# LFMXO5_25 register map
Vendor: Latticsemi.com; Series: LFMXO5; File version: 1.0
Registers are 32-bit, read-write, reset 0x0 unless marked. A register's access mark holds for its fields unless they carry their own. Offsets are from the block's base; [hi:lo] are bit positions.

## i3c_s_inst
Base 0x00010800
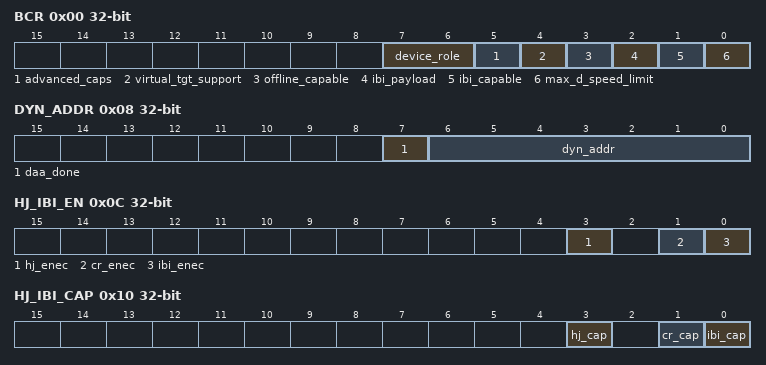
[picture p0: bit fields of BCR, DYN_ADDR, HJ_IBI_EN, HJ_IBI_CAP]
0x00 BCR ro — Target Bus Characteristics Register
  [7:6] device_role — 2'b00 - I3C Target, 2'b01 - I3C Controller-capable (Not implemented in this IP), Others - Reserved for future definition by MIPI Alliance I3C WG
  [5] advanced_caps — 0 - Does not support optional advanced capabilities., 1 - Supports optional advanced capabilities. When Target is configured with IBI capability and IBI payload, this is set to 1 for optional Pending Read MDB support.
  [4] virtual_tgt_support — 0 - Is not a Virtual Target and does not expose other downstream Device(s), 1 - Is a Virtual Target, or exposes other downstream Device(s)
  [3] offline_capable — 0 - Device will always respond to I3C Bus commands, 1 - Device will not always respond to I3C Bus Commands
  [2] ibi_payload — From IBI Payload Size attiribute. 0 - If IBI Payload Size attribute is set to 0. No data bytes follow the IBI., 1 - If IBI Payload Size attribute is set to greater than or equal to 1. One data byte (MDB) shall follow the accepted IBI, and additional data bytes may follow
  [1] ibi_capable — From IBI Capable attribute. 0 - Not capable., 1 - Capable.
  [0] max_d_speed_limit — From Maximum Data Speed Limitation attribute. 0 - No limitation., 1 - With limitation. Controller shall use GETMXDS CCC to get specific limitation from Target.
0x04 DCR ro — Target Device Characteristics Register
  [7:0] dcr — Device ID set by User through DCR attribute. 255 available codes for describing the type of sensor or Device (e.g., accelerometer, gyroscope, composite Devices). Default value is 8'b0 for generic Device.
0x08 DYN_ADDR ro — Assigned dynamic address and done flag
  [7] daa_done — 0 - DA is not yet assigned or is reset by RSTDAA CCC.,1 - DA is assigned via ENTDAA, SETNEWDA, SETAASA or SETDASA CCC
  [6:0] dyn_addr — Dynamic Address Assigned to I3C Target
0x0C HJ_IBI_EN ro — Hot-Join and IBI enable from Controller via ENEC/DISEC CCC
  [3] hj_enec — Hot-Join Enable by Controller. 0 - Target-initiated Hot-Join is not allowed on the I3C bus, 1 - Target-initiated Hot-Join is allowed on the I3C bus
  [1] cr_enec — Controller Role Request Enable by Controller. 0 - Target-initiated Controller Role Request is not allowed on the I3C bus, 1 - Target-initiated Controller Role Request is allowed on the I3C bus
  [0] ibi_enec — IBI Enable by Controller. 0 - Target-initiated interrupts are not allowed on the I3C bus, 1 - Target-initiated interrupts are allowed on the I3C bus
0x10 HJ_IBI_CAP ro — Hot-Join and IBI capability configured by User using attributes
  [3] hj_cap — 0 - Target device is configured without Hot-Join Capability, 1 - Target device is configured with Hot-Join Capability
  [1] cr_cap — 0 - Target device is configured without Secondary-Controller Capability, 1 - Target device is configured with Secondary-Controller Capability
  [0] ibi_cap — 0 - Target device is configured without IBI Capability, 1 - Target device is configured with IBI Capability
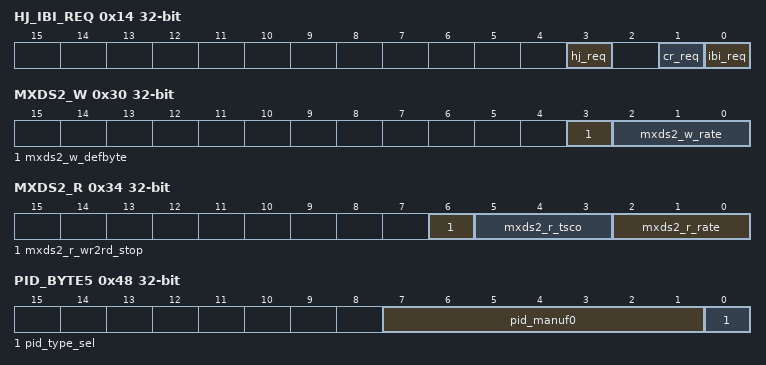
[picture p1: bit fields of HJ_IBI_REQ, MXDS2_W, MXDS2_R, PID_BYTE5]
0x14 HJ_IBI_REQ — Hot-Join and IBI request from User.
  [3] hj_req — When set to High, Target will initiate Hot-Join request at the next valid opportunity. Reset to 0 when Hot-Join is done or disabled by the Controller.
  [1] cr_req — When set to High, Target will initiate Controller Role Request at the next valid opportunity. Reset to 0 when Controller Role Request is done or disabled by the Controller.
  [0] ibi_req — When set to High, Target will initiate IBI at the next valid opportunity. Reset to 0 when IBI is done or disabled by the Controller.
0x18 HJ_IBI_RETRY — Number of retries for Hot-Join and IBI.
  [7:0] hj_ibi_retry — Indicates number of times the Target retries Hot-Join or IBI when it is NACKed by the Controller. When set to 0, number of tries is not limited.
0x1C MWL_MSB ro — Most significant byte of Maximum Write Length set by the Controller
  [7:0] mwl_msb — Most Significant Byte of maximum write length set by I3C Controller via SETMWL CCC. If SETMWL is greater than default value 512 (FIFO size), MWL will be set to 512.
0x20 MWL_LSB ro — Least significant byte of Maximum Write Length set by the Controller
  [7:0] mwl_lsb — Least Significant Byte of maximum write length set by I3C Controller via SETMWL CCC. If SETMWL is greater than default value 512 (FIFO size), MWL will be set to 512.
0x24 MRL_MSB ro — Most significant byte of Maximum Read Length set by the Controller
  [7:0] mrl_msb — Most Significant Byte of maximum read length set by I3C Controller via SETMRL CCC. If SETMRL is greater than default value 512 (FIFO size), MRL will be set to 512.
0x28 MRL_LSB ro — Least significant byte of Maximum Read Length set by the Controller
  [7:0] mrl_lsb — Least Significant Byte of maximum read length set by I3C Controller via SETMRL CCC. If SETMRL is greater than default value 512 (FIFO size), MRL will be set to 512.
0x2C MAX_IBI_PAYLD ro — Maximum IBI Payload Size set by the Controller. Applicable only when Target is configured with IBI capability and IBI payload is set to greater than or equal to 1.
  [7:0] max_ibi_payld — Maximum IBI Payload set by I3C Controller via SETMRL CCC. If value is greater than FIFO size, register will be set to FIFO size. Unlimited payload size is not supported in this IP.
0x30 MXDS2_W — Applicable only when Target is configured with Maximum Data Speed Limitation
  [3] mxds2_w_defbyte ro — 0 - Target does not support defining byte for GETMXDS CCC., 1 - Target supports defining byte for GETMXDS CCC.
  [2:0] mxds2_w_rate — Maximum Sustained Data Rate for non-CCC Messages sent by Controller Device to Target Device. 0 - fSCL Max (default value), 1 - 8 MHz, 2 - 6 MHz, 3 - 4 MHz, 4 - 2 MHz, Others - Reserved for future use by MIPI Alliance
0x34 MXDS2_R — Applicable only when Target is configured with Maximum Data Speed Limitation
  [6] mxds2_r_wr2rd_stop ro — If maximum read turnaround time is not 0, then this field is used to tell the Controller whether the Target permits the Write-to-Read to be split by a STOP. 0 - STOP would cancel the Read, 1 - The Target permits the Write-to-Read to be split by a STOP (not supported in this IP)
  [5:3] mxds2_r_tsco — Clock to Data Turnaround Time (tSCO). 0 - less than or equal to 8 ns (default value), 1 - less than or equal to 9 ns, 2 - less than or equal to 10 ns, 3 - less than or equal to 11 ns, 4 - less than or equal to 12 ns, 5, 6 - Reserved for future use by MIPI Alliance, 7 - tSCO is > 12 ns, and is reported by private agreement
  [2:0] mxds2_r_rate — Maximum Sustained Data Rate for non-CCC Messages sent by Target Device to Controller Device. 0 - fSCL Max (default value), 1 - 8 MHz, 2 - 6 MHz, 3 - 4 MHz, 4 - 2 MHz, Others - Reserved for future use by MIPI Alliance
0x38 MAX_RDTURN_B2 — Applicable only when Target is configured with Maximum Data Speed Limitation
  [7:0] max_rdturn_b2 — Maximum Read Turnaround Time in us. Most significant byte of 24-bit field that can encode turnaround times from 0.0 seconds to 16 seconds.
0x3C MAX_RDTURN_B1 — Applicable only when Target is configured with Maximum Data Speed Limitation
  [7:0] max_rdturn_b1 — Maximum Read Turnaround Time in us. Middle byte of 24-bit field that can encode turnaround times from 0.0 seconds to 16 seconds.
0x40 MAX_RDTURN_B0 — Applicable only when Target is configured with Maximum Data Speed Limitation
  [7:0] max_rdturn_b0 — Maximum Read Turnaround Time in us. Least significant byte of 24-bit field that can encode turnaround times from 0.0 seconds to 16 seconds.
0x44 PID_BYTE6 — 6th Byte of Target Device PID.
  [7:0] pid_manuf1 — Bits 14:7 of 15-bit MIPI Manufacturer ID. Reset value may be configured by User via Manufacturer ID attribute.
0x48 PID_BYTE5 — 5th Byte of Target Device PID.
  [7:1] pid_manuf0 — Bits 6:0 of 15-bit MIPI Manufacturer ID. Reset value may be configured by User via Manufacturer ID attribute.
  [0] pid_type_sel ro — Provisioned ID type selector. 0 - Vendor Fixed Value, 1 - Random value generated by device (Not supported in this IP)
0x4C PID_BYTE4 — 4th Byte of Target Device PID.
  [7:0] pid_part1 — Bits 15:8 of 16-bit Part ID when pid_type_sel is 0. The meaning of this 16-bit field is left to the Device vendor to define. Reset value may be configured by User via Part ID attribute.
0x50 PID_BYTE3 — 3rd Byte of Target Device PID.
  [7:0] pid_part0 — Bits 7:0 of 16-bit Part ID when pid_type_sel is 0. The meaning of this 16-bit field is left to the Device vendor to define. Reset value may be configured by User via Part ID attribute.
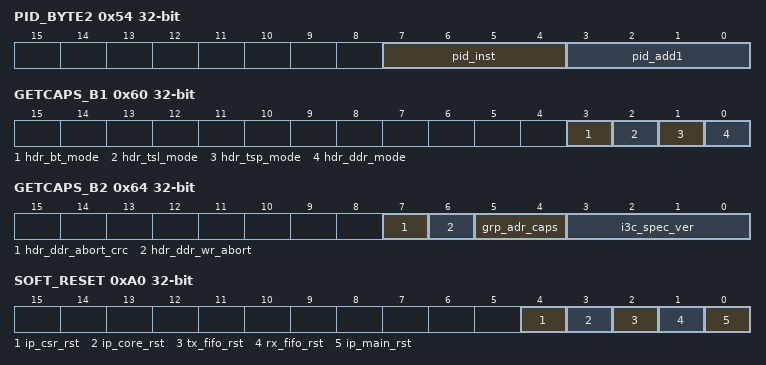
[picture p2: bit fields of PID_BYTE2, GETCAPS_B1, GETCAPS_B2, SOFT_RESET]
0x54 PID_BYTE2 — 2nd Byte of Target Device PID.
  [7:4] pid_inst — Instance ID field that should identify the individual Device, using a method selected by the system designer (e.g., straps, fuses, non-volatile memory, or another appropriate method). Reset value may be configured by User via Instance ID attribute.
  [3:0] pid_add1 — Bits 11:8 of 12-bit Additional ID for definitions with additional meaning (e.g., Deeper device characteristics that may optionally include Device Characteristics Register values). Reset value may be configured by User via Additional ID attribute.
0x58 PID_BYTE1 — 1st Byte of Target Device PID.
  [7:0] pid_add0 — Bits 7:0 of 12-bit Additional ID for definitions with additional meaning (e.g., Deeper device characteristics that may optionally include Device Characteristics Register values). Reset value may be configured by User via Additional ID attribute.
0x5C STAT_ADDR — 1st Byte of Target Device PID.
  [6:0] stat_addr — Target Static Address assigned by User. Reset value may be configured by User via Static Address attribute. If static address is disabled, reset value is 0.
0x60 GETCAPS_B1 ro — Device capabilities that Target returns when Controller sends GETCAPS CCC.
  [3] hdr_bt_mode — Fixed to 0. HDR-BT mode is not supported.
  [2] hdr_tsl_mode — Fixed to 0. HDR-BT mode is not supported.
  [1] hdr_tsp_mode — Fixed to 0. HDR-BT mode is not supported.
  [0] hdr_ddr_mode — Set to 1 when device is configured with HDR capability. Only HDR-DDR mode is supported.
0x64 GETCAPS_B2 ro — Device capabilities that Target returns when Controller sends GETCAPS CCC.
  [7] hdr_ddr_abort_crc — I3C Target capability of emitting the CRC Word when a transaction in HDR-DDR Mode is aborted. Set to 1 when device is configured with HDR capability. 0 - No, 1 - Yes
  [6] hdr_ddr_wr_abort — I3C Target capability of issuing the Write Abort in HDR-DDR Mode. Set to 1 when device is configured with HDR capability. 0 - No, 1 - Yes
  [5:4] grp_adr_caps — Indicates the Group Address function capabilities of this I3C Device. Fixed to 0. IP does not support Group Address function.
  [3:0] i3c_spec_ver — Indicates the minor version number of the MIPI I3C Specification with which this I3C v1.x Device complies (i.e., the 'x' in I3C v1.x). Setting to 0x is illegal.
0x68 GETCAPS_B3 ro — Device capabilities that Target returns when Controller sends GETCAPS CCC.
  [6] pend_rd_mdb — I3C Target support for IBI with Pending Read Notification MDB, which the Controller shall then follow with a Private Read request to fetch the data. Set to 1 when device is configured with IBI with MDB capability. 0 - No, 1 - Yes
  [6:5] hdr_bt_crc32 — I3C Target support CRC-32 data integrity verification in HDR Bulk Transport Mode. 0 - No, 1 - Yes (Not supported in this IP)
  [6:4] getstatus_defbyte — I3C Target support for defining byte in GETSTATUS CCC. 0 - No, 1 - Yes (Not supported in this IP)
  [6:3] getcaps_defbyte — I3C Target support for defining byte in GETCAPS CCC. 0 - No, 1 - Yes (Not supported in this IP)
  [6:2] d2dxfer_ibi — I3C Target capability to initiate Device to Device (D2D) Transfer using IBI with MDB 0x37. 0 - No, 1 - Yes (Not supported in this IP)
  [6:1] d2dxfer — I3C Target support for D2D transfers either as a Source or a Subscriber/Receiver. 0 - No, 1 - Yes (Not supported in this IP)
  [6:0] ml_data_xfer — I3C Target support for Multi-Lane data transfer. 0 - No, 1 - Yes (Not supported in this IP)
0x70 OSC_INACCURACY — Inaccuracy of Target's internal oscillator.
  [7:0] osc_inaccuracy — Describes the maximum variation of the Target's internal oscillator in 1/10th percent (0.1%) increments, up to 25.5%.
0x80 RX_FIFO ro — Receive FIFO
  [7:0] rx_fifo — Data bytes received from I3C bus are stored in this FIFO. User can get the received data by reading from this address multiple times depending on the number of data bytes to be read. User may read rxfifo_not_empty interrupt status register (Interrupt Status 2 Bit 6) first to determine if there is data to be read from rx_fifo.
0x88 TX_FIFO — Transmit FIFO
  [7:0] tx_fifo — Data to be sent to I3C bus are stored in this FIFO. User can do multiple writes to this address depending on the number of data bytes to be written. Reading from this address will indicate txfifo_empty status (0x1 - Empty, 0x - Not Empty).
0xA0 SOFT_RESET
  [4] ip_csr_rst — When set to high, resets the IP read-write and write-only registers only. Auto-clear.
  [3] ip_core_rst — When set to high, resets the internal state of I3C Target Core only (including Tx and Rx FIFO). Dynamic address and configurations via CCCs are not reset.
  [2] tx_fifo_rst — When set to high, resets the Tx FIFO only. Auto-clear.
  [1] rx_fifo_rst — When set to high, resets the Rx FIFO only. Auto-clear.
  [0] ip_main_rst — When set to high, resets the whole IP including registers, FIFO, dynamic address, and CCC configurations. Auto-clear.
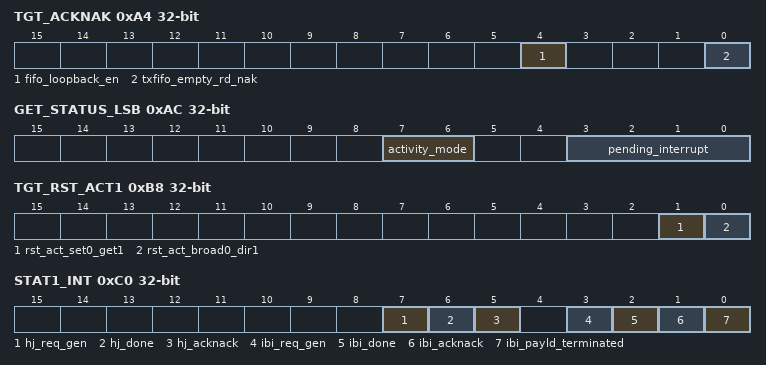
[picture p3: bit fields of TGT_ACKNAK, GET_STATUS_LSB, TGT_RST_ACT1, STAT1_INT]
0xA4 TGT_ACKNAK — Target Response
  [4] fifo_loopback_en — 0 - Data written through Private Write will be read from Rx FIFO. Data written to Tx FIFO will be read through Private Read. 1 - Data written through Private Write will be stored in Rx FIFO and transferred to Tx FIFO to be read through Private Read. Data written to the Tx FIFO by the User can still be read through Private Read.
  [0] txfifo_empty_rd_nak — Target response when Controller reads but Tx FIFO is empty 0 - In SDR mode, Target will ACK its Address and return 0xFF read data then End-of-Message by pulling SDA Low at T-bit. If I3C bus is in HDR mode and Target is configured with HDR capability, Target will ACK its address and return 0x data then end Read. 1 - Target will NACK its Address
0xA8 GET_STATUS_MSB — Most significant byte that the Target returns when Controller sends GETSTATUS CCC
  [7:0] get_status_msb — Reserved for vendor-specific meaning.
0xAC GET_STATUS_LSB — Least significant byte that the Target returns when Controller sends GETSTATUS CCC
  [7:6] activity_mode — Contains the 2-bit ID of the Target Device's current activity mode. For Target devices without secondary controller capability, the meanings of this value will depend upon a private contract between the Target and the Controller.
  [3:0] pending_interrupt — Contains the interrupt number of any pending interrupt, or 0 if no interrupts are pending.
0xB0 BUS_ACT_STATE ro — Least significant byte that the Target returns when Controller sends GETSTATUS CCC
  [1:0] bus_act — When bus_act_rcvd is set to 1, this register indicates the activity state received. Write 1 to clear. 0 - 1 us (Latency-free,operation), 1 - 100 us, 2 - 2ms, 3 - 50ms (Lowest-activity operation)
0xB4 TGT_RST_ACT0 ro — Target Reset Action Information 1
  [7:0] rst_act — Target Reset Action configured by the Controller via Defining Byte of RSTACT CCC. When Target Reset Pattern is received after RSTACT CCC, User shall perform the configured reset action.
0xB8 TGT_RST_ACT1 ro — Target Reset Action Information 2
  [1] rst_act_set0_get1 — 0 - Controller configured Target Reset Action by Direct SET RSTACT CCC, 1 - Controller configured Target Reset Action by Direct GET RSTACT CCC
  [0] rst_act_broad0_dir1 — 0 - Controller configured Target Reset Action by Broadcast RSTACT CCC, 1 - Controller configured Target Reset Action by Direct Set/Get RSTACT CCC
0xBC TGT_RST_ACT2 ro — Target Reset Action Information 3
  [7:0] rst_act_set — Target Reset Action configured by the Controller via Defining Byte of Direct SET RSTACT CCC. This is the value returned by Target when Controller sends Direct GET CCC.
0xC0 STAT1_INT — Interrupt Status 1
  [7] hj_req_gen — When set to 1, Hot-Join request is generated by Target. Write 1 to clear.
  [6] hj_done — When set to 1, Hot-Join address with Write bit is transmitted by Target and Controller has either ACKed or NACKed for HJ_IBI_RETRY times. Write 1 to clear.
  [5] hj_acknack — When set to 1, Hot-Join is NACKed by Controller after HJ_IBI_RETRY times. Write 1 to clear.
  [3] ibi_req_gen — When set to 1, IBI request is generated by Target. Write 1 to clear.
  [2] ibi_done — When set to 1, Target Address with Read bit has been transmitted by Target and Controller has either ACKED or NACKed the request for HJ_IBI_RETRY times. If with payload, IBI payload has been transmitted and finished either by End-of-Data (from Target) or STOP (from Controller). Write 1 to clear.
  [1] ibi_acknack — When set to 1, IBI is NACKed by Controller after HJ_IBI_RETRY times. Write 1 to clear.
  [0] ibi_payld_terminated — When set to 1, Controller aborted reading complete IBI payload. Write 1 to clear.
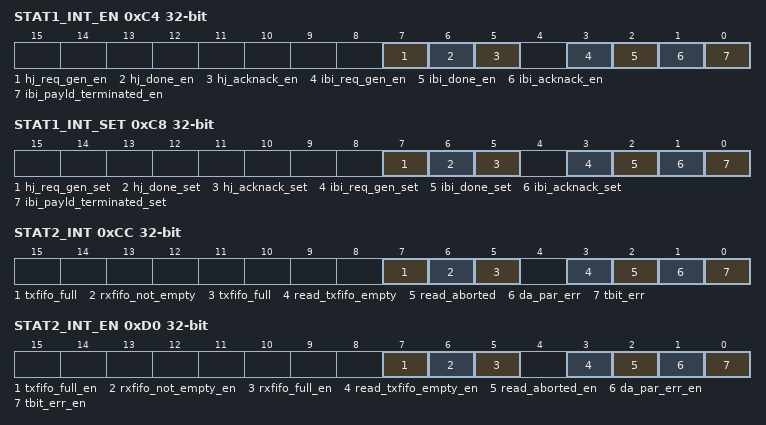
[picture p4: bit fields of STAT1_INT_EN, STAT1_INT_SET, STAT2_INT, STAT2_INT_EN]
0xC4 STAT1_INT_EN — Interrupt Status Enable 1
  [7] hj_req_gen_en — When set to 1, corresponding interrupt status 1 is enabled.
  [6] hj_done_en — When set to 1, corresponding interrupt status 1 is enabled.
  [5] hj_acknack_en — When set to 1, corresponding interrupt status 1 is enabled.
  [3] ibi_req_gen_en — When set to 1, corresponding interrupt status 1 is enabled.
  [2] ibi_done_en — When set to 1, corresponding interrupt status 1 is enabled.
  [1] ibi_acknack_en — When set to 1, corresponding interrupt status 1 is enabled.
  [0] ibi_payld_terminated_en — When set to 1, corresponding interrupt status 1 is enabled.
0xC8 STAT1_INT_SET wo — Interrupt Status Set 1
  [7] hj_req_gen_set — Manually set corresponding interrupt status 1 to 1.
  [6] hj_done_set — Manually set corresponding interrupt status 1 to 1.
  [5] hj_acknack_set — Manually set corresponding interrupt status 1 to 1.
  [3] ibi_req_gen_set — Manually set corresponding interrupt status 1 to 1.
  [2] ibi_done_set — Manually set corresponding interrupt status 1 to 1.
  [1] ibi_acknack_set — Manually set corresponding interrupt status 1 to 1.
  [0] ibi_payld_terminated_set — Manually set corresponding interrupt status 1 to 1.
0xCC STAT2_INT — Interrupt Status 2
  [7] txfifo_full — When set to 1, it indicates Tx FIFO is full. Write 1 to clear.
  [6] rxfifo_not_empty — When set to 1, it indicates that Rx FIFO is not empty. Write 1 to clear.
  [5] txfifo_full — When set to 1, it indicates Rx FIFO is full. Write 1 to clear.
  [3] read_txfifo_empty — When set to 1, Controller initiated Read but Tx FIFO is empty. Write 1 to clear.
  [2] read_aborted — When set to 1, Read is aborted early by Controller. Write 1 to clear.
  [1] da_par_err — When set to 1, parity bit error in dynamic address assignment occurred. Write 1 to clear.
  [0] tbit_err — When set to 1, data T-bit Error occurred. Write 1 to clear.
0xD0 STAT2_INT_EN — Interrupt Status Enable 2
  [7] txfifo_full_en — When set to 1, corresponding interrupt status 2 is enabled.
  [6] rxfifo_not_empty_en — When set to 1, corresponding interrupt status 2 is enabled.
  [5] rxfifo_full_en — When set to 1, corresponding interrupt status 2 is enabled.
  [3] read_txfifo_empty_en — When set to 1, corresponding interrupt status 2 is enabled.
  [2] read_aborted_en — When set to 1, corresponding interrupt status 2 is enabled.
  [1] da_par_err_en — When set to 1, corresponding interrupt status 2 is enabled.
  [0] tbit_err_en — When set to 1, corresponding interrupt status 2 is enabled.
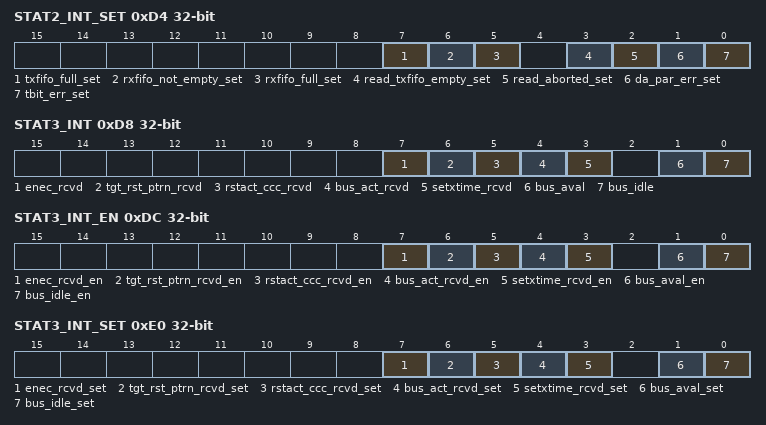
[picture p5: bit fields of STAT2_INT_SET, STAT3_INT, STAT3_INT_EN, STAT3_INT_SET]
0xD4 STAT2_INT_SET wo — Interrupt Status Set 2
  [7] txfifo_full_set — Manually set corresponding interrupt status 2 to 1.
  [6] rxfifo_not_empty_set — Manually set corresponding interrupt status 2 to 1.
  [5] rxfifo_full_set — Manually set corresponding interrupt status 2 to 1.
  [3] read_txfifo_empty_set — Manually set corresponding interrupt status 2 to 1.
  [2] read_aborted_set — Manually set corresponding interrupt status 2 to 1.
  [1] da_par_err_set — Manually set corresponding interrupt status 2 to 1.
  [0] tbit_err_set — Manually set corresponding interrupt status 2 to 1.
0xD8 STAT3_INT — Interrupt Status 3
  [7] enec_rcvd — When set to 1, Target received Broadcast/Direct ENEC/DISEC CCC from Controller. Write 1 to clear.
  [6] tgt_rst_ptrn_rcvd — When set to 1, Target received Target Reset Pattern from Controller. Write 1 to clear.
  [5] rstact_ccc_rcvd — When set to 1, Target received RSTACT CCC from Controller. Write 1 to clear.
  [4] bus_act_rcvd — When set to 1, Target received ENTASx CCC from Controller Write 1 to clear.
  [3] setxtime_rcvd — When set to 1, Target received SETXTIME with supported sub-command byte from Controller. Write 1 to clear.
  [1] bus_aval — When set to 1, I3C bus is in Bus Available condition. Write 1 to clear.
  [0] bus_idle — When set to 1, I3C bus is in Bus Idle condition. Write 1 to clear.
0xDC STAT3_INT_EN — Interrupt Status Enable 3
  [7] enec_rcvd_en — When set to 1, corresponding interrupt status 3 is enabled.
  [6] tgt_rst_ptrn_rcvd_en — When set to 1, corresponding interrupt status 3 is enabled.
  [5] rstact_ccc_rcvd_en — When set to 1, corresponding interrupt status 3 is enabled.
  [4] bus_act_rcvd_en — When set to 1, corresponding interrupt status 3 is enabled.
  [3] setxtime_rcvd_en — When set to 1, corresponding interrupt status 3 is enabled.
  [1] bus_aval_en — When set to 1, corresponding interrupt status 3 is enabled.
  [0] bus_idle_en — When set to 1, corresponding interrupt status 3 is enabled.
0xE0 STAT3_INT_SET wo — Interrupt Status Set 3
  [7] enec_rcvd_set — Manually set corresponding interrupt status 3 to 1.
  [6] tgt_rst_ptrn_rcvd_set — Manually set corresponding interrupt status 3 to 1.
  [5] rstact_ccc_rcvd_set — Manually set corresponding interrupt status 3 to 1.
  [4] bus_act_rcvd_set — Manually set corresponding interrupt status 3 to 1.
  [3] setxtime_rcvd_set — Manually set corresponding interrupt status 3 to 1.
  [1] bus_aval_set — Manually set corresponding interrupt status 3 to 1.
  [0] bus_idle_set — Manually set corresponding interrupt status 3 to 1.
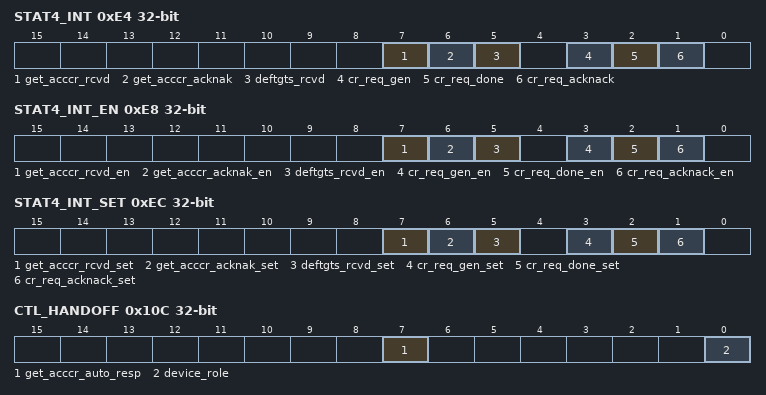
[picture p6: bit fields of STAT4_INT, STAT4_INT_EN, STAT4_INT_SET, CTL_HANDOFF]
0xE4 STAT4_INT — Interrupt Status 4
  [7] get_acccr_rcvd — When set to 1, Target received GET_ACCCR CCC from Controller. Write 1 to clear.
  [6] get_acccr_acknak — When set to 1, Target NACKed GET_ACCCR CCC received from Controller. Write 1 to clear.
  [5] deftgts_rcvd — When set to 1, Target received DEFTGTS CCC from Controller (including data bytes describing each device in the bus). Write 1 to clear.
  [3] cr_req_gen — When set to 1, Controller Role request is generated by Target . Write 1 to clear.
  [2] cr_req_done — When set to 1, Target Address with Write bit has been transmitted by Target and Controller has either ACKed or NACKed the request for HJ_IBI_RETRY times. Write 1 to clear.
  [1] cr_req_acknack — When set to 1, Controller Role request is NACKed by Controller after HJ_IBI_RETRY times. Write 1 to clear.
0xE8 STAT4_INT_EN — Interrupt Status Enable 4
  [7] get_acccr_rcvd_en — When set to 1, corresponding interrupt status 4 is enabled.
  [6] get_acccr_acknak_en — When set to 1, corresponding interrupt status 4 is enabled.
  [5] deftgts_rcvd_en — When set to 1, corresponding interrupt status 4 is enabled.
  [3] cr_req_gen_en — When set to 1, corresponding interrupt status 4 is enabled.
  [2] cr_req_done_en — When set to 1, corresponding interrupt status 4 is enabled.
  [1] cr_req_acknack_en — When set to 1, corresponding interrupt status 4 is enabled.
0xEC STAT4_INT_SET wo — Interrupt Status Set 4
  [7] get_acccr_rcvd_set — Manually set corresponding interrupt status 4 to 1.
  [6] get_acccr_acknak_set — Manually set corresponding interrupt status 4 to 1.
  [5] deftgts_rcvd_set — Manually set corresponding interrupt status 4 to 1.
  [3] cr_req_gen_set — Manually set corresponding interrupt status 4 to 1.
  [2] cr_req_done_set — Manually set corresponding interrupt status 4 to 1.
  [1] cr_req_acknack_set — Manually set corresponding interrupt status 4 to 1.
0x100 DEFTGTS_COUNT ro — Count information sent by the Active Controller via DEFTGTS CCC
  [7:0] deftgts_count — Describes the number of Targets and Groups present in the I3C bus.
0x104 DEFTGTS_RXFIFO_S ro — Pointer for start address of DEFTGTS data in Rx FIFO.
  [7:0] rxfifo_deftgts_start — Count N indicates number of times User needs to read from Rx FIFO before DEFTGTS data is read. When equal to 0, next read data is start of DEFTGTS data.
0x108 DEFTGTS_RXFIFO_C ro — Number of DEFTGTS data bytes stored in Rx FIFO.
  [7:0] rxfifo_deftgts_count — Indicates number of DEFTGTS data bytes stored in Rx FIFO. When reading of DEFTGTS data is started (rxfifo_deftgts_start is equal to 8'h0), this count decreases by one every Rx FIFO read. When 0 count is reached, all DEFTGTS data has been read from Rx FIFO.
0x10C CTL_HANDOFF — Target configuration for Controller Role Handoff
  [7] get_acccr_auto_resp — Target auto-response when receiving GETACCCR CCC. Default response is NACK. 0 - Target will ACK the GETACCCR CCC, 1 - Target will NACK the GETACCCR CCC
  [0] device_role — Current device role. User may write to this register to reset the device role (may be used when the system loses information on the device role). 0 - Device is acting as Target, 1 - Device is acting as Controller
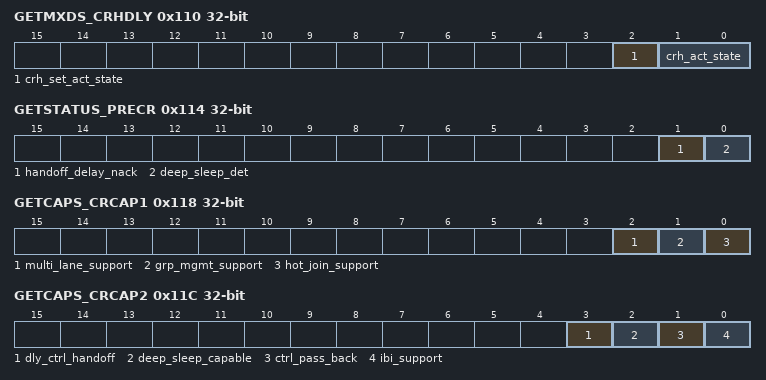
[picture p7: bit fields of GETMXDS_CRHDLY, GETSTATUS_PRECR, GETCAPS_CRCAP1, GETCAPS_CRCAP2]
0x110 GETMXDS_CRHDLY — Return value for GETMXDS when defining byte is 0x91.
  [2] crh_set_act_state — Indicates whether the Active Controller should set the Bus to a certain Activity State before passing the Controller Role to this device. 0 - Active Controller should not set the bus to any Activity State before passing the Controller Role to this Device, 1 - Active Controller should set the bus to the Activity State set in bits 1:0 before passing the Controller Role to this Device
  [1:0] crh_act_state — When crh_set_act_state is set to 1, this indicates whether the device initially acts with a given Activity State after becoming the Active Controller on the Bus. The indicated Activity State implies that the Device may have a delayed response to Bus activity, and so the former Controller should wait the specified delay time for the indicated Activity State before testing this Device, to confirm that it is controlling the Bus before initiating the CE3 error recovery flow.
0x114 GETSTATUS_PRECR — Return value for GETSTATUS when defining byte is 0x91.
  [1] handoff_delay_nack — Indicates whether this Device is currently processing any DEFTGTS CCC Broadcasts that may have been sent by the Active Controller. 0 - The Device is not currently processing Broadcast data and can safely accept the Controller Role. 1 - The Device is currently processing DEFTGTS and may be updating its internal state. Active Controller may wait to send GETACCCR CCC to this Device or should at least be aware that any attempts to send GETACCCR CCC to this Device will be met with a NACK response until this bit is read again later with a value of 1'b0.
  [0] deep_sleep_det — Indicates whether the device has entered a deep sleep state in which it may have missed any DEFTGTS CCC sent by the Active controller. Consequently, this device's internal state of known Target devices should be considered outdated. 0 - The device has not entered a deep sleep state., 1 - The device has entered a deep sleep state. The Active Controller shall send another DEFTGTS CCC to update the device's internal state before sending GETACCCR CCC.
0x118 GETCAPS_CRCAP1 ro — Return value for GETCAPS when defining byte is 0x91.
  [2] multi_lane_support — Indicates that device may use the MLANE CCC to change ML configuration of other I3C Targets. Not supported in this IP.
  [1] grp_mgmt_support — Indicatest that device supports Group Address handoff or management capabilities. (Not supported in this IP).
  [0] hot_join_support — Indicates that The device may support Hot-Join and will ACK an I3C Target Hot-Join request while it is the Active Controller on the Bus. Fixed to 1.
0x11C GETCAPS_CRCAP2 — Return value for GETCAPS when defining byte is 0x91.
  [3] dly_ctrl_handoff ro — 0 - The device does not need additional time to process Broadcast CCC data from the Active Controller. The Active Controller may expect it to ACK the GETACCCR CCC as part of the Controller Role Handoff procedure even if the device did not initially send a Controller Role Request. 1 - The device may need additional time processing data from the Controller. The Active Controller shall periodically check the value returned by GETSTATUS with 0x91 to determine if the device is ready to accept the Controller Role.
  [2] deep_sleep_capable — 0 - The device shall remain active and continue to monitor the I3C bus to listen for Broadcast CCCs sent by the Active Controller and shall not enter a deep sleep state from which it must be resynchronized by the Active Controller before it can accept the Controller role. 1 - The device may enter a deep sleep state during which it may miss some Broadcast DEFTGTS sent by the Active Controller. This will require resynchronization upon re-entering a normal operating state before it can accept the Controller Role.
  [1] ctrl_pass_back — 0 - The device shall not automatically pass the Controller Role back to the former Active Controller and shall support a Controller Role request from any Controller-capable device., 1 - The device shall automatically pass the Controller Role back to the former Active Controller from which it received its Controller Role. This is done via GETACCCR CCC once it has finished performing any tasks that require it to request and gain the Controller Role. This device shall support a Controller Role request from any Controller-capable device.
  [0] ibi_support ro — Indicates that device may support IBI and will ACK an I3C Target IBI while it is the Active Controller on the Bus. Fixed to 1.
0x140 BUS_MODE ro — I3C Bus Mode
  [0] bus_hdr_mode — When equal to High, I3C Bus is in HDR mode.
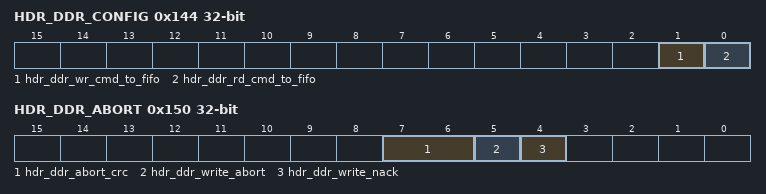
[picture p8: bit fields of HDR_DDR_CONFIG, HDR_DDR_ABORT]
0x144 HDR_DDR_CONFIG — HDR-DDR Target Configuration for received HDR data
  [1] hdr_ddr_wr_cmd_to_fifo — Applicable only when Target is configured with HDR capability. When set to High, HDR-DDR Write Command is stored to Rx FIFO.
  [0] hdr_ddr_rd_cmd_to_fifo — Applicable only when Target is configured with HDR capability. When set to High, HDR-DDR Read Command is stored to Rx FIFO.
0x150 HDR_DDR_ABORT ro — HDR-DDR Abort Configuration set by Controller via ENDXFER CCC
  [7:6] hdr_ddr_abort_crc — Applicable only when Target is configured with HDR capability. When set to High, Target is capable of emitting the CRC Word when a transaction in HDR-DDR Mode is aborted.
  [5] hdr_ddr_write_abort — Applicable only when Target is configured with HDR capability. When set to High, Target is capable of issuing the Write Abort in HDR-DDR Mode. This IP will issue Write Abort in HDR-DDR Mode if the Rx FIFO is full.
  [4] hdr_ddr_write_nack — Applicable only when Target is configured with HDR capability. When set to High, Target is capable of issuing a NACK to an HDR-DDR Write Command. This IP will issue NACK an HDR-DDR Write Command if the Rx FIFO is full.
